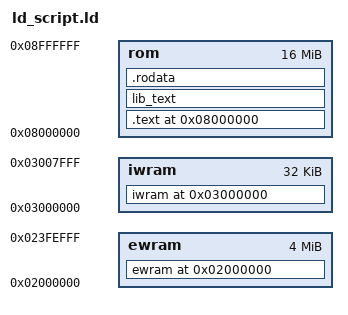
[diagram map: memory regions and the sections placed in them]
OUTPUT_FORMAT("elf32-littlearm", "elf32-bigarm", "elf32-littlearm")
OUTPUT_ARCH(arm)
MEMORY {
    ewram   : ORIGIN = 0x02000000, LENGTH = 4M - 4k
    iwram   : ORIGIN = 0x03000000, LENGTH = 32k
		rom     : ORIGIN = (0x08000000), LENGTH = 16M
}

SOUND_INFO_PTR = 0x03007FF0;

gMaxLines = 0;
gNumMusicPlayers = 32;

SECTIONS {
	. = 0x2000000;
	ewram (NOLOAD) :
	ALIGN(4)
    {
      gHeap = .;
      . = 0x20400;
      src/main.o(ewram_data);
      src/bg.o(ewram_data);
      src/camera.o(ewram_data);
      src/font.o(ewram_data);
      src/video.o(ewram_data);
      src/registry.o(ewram_data);
      src/utility_08237468.o(ewram_data);
      src/vm.o(ewram_data);
      src/code_08230e88.o(ewram_data);
      src/link.o(ewram_data);
      src/entity_0804e2c0.o(ewram_data);
    } >ewram = 0x00

	. = 0x3000000;
    iwram (NOLOAD) :
    ALIGN(4)
    {
      src/entity_08000a94.o(iwram_data);
      src/entity_08001610.o(iwram_data);
      src/main.o(iwram_data);
      src/entity_d9ae.o(iwram_data);
      src/entity_08004fac.o(iwram_data);
      src/message_choice.o(iwram_data);
      src/map_item.o(iwram_data);
      src/breakable.o(iwram_data);
      src/entity_2d2b.o(.bss);
      src/duneyrr_chandelier.o(.bss);
      src/entity_83b2.o(iwram_data);
      src/entity_0866.o(iwram_data);
      src/spirit_bugs.o(.bss);
      src/entity_329b.o(iwram_data);
      src/sun_countdown.o(iwram_data);
      src/shadow_normal.o(.bss);
      src/shadow_large.o(.bss);
      src/entity_080146e0.o(iwram_data);
      src/entity_08015220.o(iwram_data);
      src/entity_08015584.o(iwram_data);
      src/entity_08016ba4.o(iwram_data);
      src/mosaic_fader.o(.bss);
      src/item_icon_popup.o(.bss);
      src/entity_e435.o(iwram_data);
      src/weather.o(.bss);
      src/entity_517b.o(iwram_data);
      src/bgp_blend.o(iwram_data);
      src/entity_4b15.o(iwram_data);
      src/entity_12c4.o(iwram_data);
      src/entity_da0b.o(iwram_data);
      . = ALIGN(8);
      src/boss.o(iwram_data);
      src/entity_ab4e.o(iwram_data);
      src/message_window.o(iwram_data);
      src/text_marquee.o(iwram_data);
      src/text_panel.o(iwram_data);
      src/text_slideshow.o(iwram_data);
      src/joyspot.o(iwram_data);
      src/entity_0804e2c0.o(iwram_data);
      src/signal_strength_icon.o(iwram_data);
      src/entity_d53d.o(iwram_data);
      . = ALIGN(8);
      src/crossover_af33.o(iwram_data);
      src/entity_08051b70.o(iwram_data);
      src/entity_723e.o(iwram_data);
      src/entity_5645.o(.bss);
      src/entity_d438.o(.bss);
      src/dust.o(.bss);
      src/entity_08058ffc.o(iwram_data);
      src/damage_number.o(.bss);
      src/entity_08060470.o(iwram_data);
      src/explosion.o(iwram_data);
      src/menu.o(iwram_data);
      src/entity_5ccc.o(iwram_data);
      src/entity_1dbe.o(.bss);
      src/entity_ef66.o(iwram_data);
      src/entity_cf58.o(iwram_data);
      src/gameover.o(iwram_data);
      src/level_upper.o(iwram_data);
      src/entity_b3d1.o(iwram_data);
      src/emote.o(iwram_data);
      src/entity_080db520.o(iwram_data);
      src/entity_080dbe54.o(iwram_data);
      src/entity_080dc44c.o(iwram_data);
      src/entity_080dd1f8.o(iwram_data);
      src/attack_box.o(iwram_data);
      src/eff_smoke.o(.bss);
      src/entity_080df420.o(iwram_data);
      src/entity_080e01bc.o(iwram_data);
      src/entity_778b.o(iwram_data);
      src/enemy_target.o(.bss);
      src/entity_081d0e20.o(iwram_data);
      src/entity_081d16ec.o(iwram_data);
      src/entity_081d2180.o(iwram_data);
      src/elevator.o(iwram_data);
      src/bee_nest.o(iwram_data);
      src/entity_c60f.o(iwram_data);
      src/entity_7b9f.o(iwram_data);
      src/entity_8cc7.o(iwram_data);
      src/link_battle_lobby.o(.bss);
      src/entity_9a9f.o(iwram_data);
      src/link_battle_coin.o(iwram_data);
      src/entity_081e9cac.o(iwram_data);
      src/entity_081ea120.o(.bss);
      src/entity_081ea820.o(.bss);
      src/flamethrower.o(.bss);
      src/entity_081eb2f0.o(.bss);
      src/entity_081edcc4.o(.bss);
      src/entity_081ee2a0.o(.bss);
      src/entity_081ee7a8.o(.bss);
      src/entity_081eeb28.o(.bss);
      src/entity_081eee80.o(.bss);
      src/entity_081efa9c.o(.bss);
      src/entity_081f0298.o(.bss);
      src/entity_081f0b90.o(.bss);
      src/entity_081f1770.o(.bss);
      src/entity_081f26bc.o(.bss);
      src/entity_081f3324.o(.bss);
      src/entity_081f4554.o(.bss);
      src/entity_081f53a8.o(.bss);
      src/entity_081f73ec.o(.bss);
      src/entity_081f7974.o(.bss);
      src/entity_081f7de4.o(.bss);
      src/entity_081f8a28.o(.bss);
      src/entity_081f959c.o(.bss);
      src/entity_081f9cb8.o(.bss);
      src/entity_081fa164.o(.bss);
      src/entity_082034c0.o(.bss);
      src/entity_08203ad0.o(.bss);
      src/entity_08204cb8.o(.bss);
      src/actor/kuro.o(.bss);
      src/entity_8aab.o(iwram_data);
      . = ALIGN(8);
      src/interrupts.o(.bss);
      . = ALIGN(8);
      src/video.o(iwram_data);
      src/bg.o(iwram_data);
      src/video_reg.o(iwram_data);
      . = ALIGN(8);
      src/font.o(iwram_data);
      src/system_0823071c.o(iwram_data);
      src/code_08230e88.o(iwram_data);
      . = ALIGN(8);
      src/vm.o(iwram_data);
      src/vm_ctrl1.o(iwram_data);
      src/collision_map.o(iwram_data);
      src/hitbox.o(iwram_data);
      . = ALIGN(8);
      src/link.o(iwram_data);
      . = ALIGN(8);
      src/rfu.o(iwram_data);
      . = ALIGN(8);
      src/entity_0823acbc.o(iwram_data);
      src/vm_ctrl2.o(.bss);
      src/vm_subroutine.o(.bss);
      src/mover.o(.bss);
      src/entity_08240a54.o(.bss);
      src/entity_794c.o(.bss);
      src/zonelist.o(.bss);
      src/solar.o(.bss);
      src/eeprom.o(.bss);
      src/sound.o(.bss);
      src/eff_082473e0.o(.bss);
      src/solar_sensor.o(.bss);
      src/lib/libagbrtc.o(.bss);
      *libgcc.a:dp-bit.o(.bss);
      *libgcc.a:fp-bit.o(.bss);
      *libc.a:syscalls.o(.bss);
      src/lib/m4a.o(.bss.code);
      src/map_pltt_4ae5.o(COMMON);
      src/entity_6978.o(COMMON);
      src/cactus.o(COMMON);
      src/entity_c9bc.o(COMMON);
      src/entity_0800f110.o(COMMON);
      src/shadow_scripted.o(COMMON);
      src/entity_08016660.o(COMMON);
      src/weather.o(COMMON);
      src/msgbus.o(COMMON);
      src/actor.o(COMMON);
      src/joyspot.o(COMMON);
      src/entity_0804e2c0.o(COMMON);
      . = ALIGN(8);
      src/player.o(COMMON);
      src/enemy_entity_5941.o(COMMON);
      src/sabata_blackhole.o(COMMON);
      src/coffin.o(COMMON);
      src/menu.o(COMMON);
      src/entity_a628.o(COMMON);
      src/tasty_water.o(COMMON);
      src/solar_plant.o(COMMON);
      src/entity_3117.o(COMMON);
      src/entity_8af6.o(COMMON);
      src/entity_4063.o(COMMON);
      src/entity_080acd4c.o(COMMON);
      src/pile_driver.o(COMMON);
      src/enemy_manager.o(COMMON);
      src/link_connect.o(COMMON);
      src/entity_9a9f.o(COMMON);
      src/link_shop.o(COMMON);
      src/boss/dvalinn.o(COMMON);
      src/actor/otenko.o(COMMON);
      . = ALIGN(8);
      src/opening_runner.o(COMMON);
      src/video.o(COMMON);
      . = ALIGN(16);
      src/interrupts.o(COMMON);
      src/iwram2.o(COMMON);
      src/link.o(COMMON);
      src/lib/linkManager.o(COMMON);
      src/code_0823cd04.o(COMMON);
      src/camera.o(COMMON);
      src/time.o(COMMON);
      src/sound.o(COMMON);
      src/zonelist.o(COMMON);
      src/solar.o(COMMON);
      src/eeprom.o(COMMON);
      src/lib/m4a.o(COMMON);
      src/solar_sensor.o(COMMON);
      src/lib/librfu_stwi.o(iwram_data);
      . = ALIGN(16);
      src/lib/librfu_rfu.o(iwram_data);
      src/lib/librfu_sio32id.o(iwram_data);
      src/lib/agb_eeprom.o(iwram_data);
      end = .;
      *libc.a:sbrkr.o(COMMON);
    } >iwram = 0x00

    . = 0x8000000;
    .text :
    ALIGN(4)
    {
      src/rom_header.o (.text);
      src/crt0.o (.text);
			src/main.o (.text);
			src/entity_08000a94.o (.text);
			src/entity_08001610.o (.text);
			src/map_pltt_4ae5.o (.text);
			src/entity_6978.o (.text);
			src/entity_e28b.o (.text);
			src/entity_d9ae.o (.text);
			src/entity_08004fac.o (.text);
			src/message_choice.o (.text);
			src/map_item.o (.text);
			src/breakable.o (.text);
			src/entity_2d2b.o (.text);
			src/duneyrr_chandelier.o (.text);
			src/entity_83b2.o (.text);
			src/entity_0866.o (.text);
			src/spirit_bugs.o (.text);
			src/solar_bamboo.o (.text);
			src/cactus.o (.text);
			src/entity_c9bc.o (.text);
			src/entity_55c2.o (.text);
			src/entity_0800f110.o (.text);
			src/dungeon_title.o (.text);
			src/obp_blend.o (.text);
			src/entity_329b.o (.text);
			src/sun_countdown.o (.text);
			src/password_decoder.o (.text);
			src/save_sequence.o (.text);
			src/entity_e534.o (.text);
			src/password.o (.text);
			src/entity_ec96.o (.text);
			src/shadow_normal.o (.text);
			src/shadow_large.o (.text);
			src/shadow_scripted.o (.text);
			src/entity_080146e0.o (.text);
			src/entity_08015220.o (.text);
			src/entity_08015584.o (.text);
			src/entity_08016660.o (.text);
			src/entity_08016ba4.o (.text);
			src/mosaic_fader.o (.text);
			src/item_icon_popup.o (.text);
			src/entity_e435.o (.text);
			src/weather.o (.text);
			src/entity_517b.o (.text);
			src/entity_cf82.o (.text);
			src/entity_5e27.o (.text);
			src/bgp_blend.o (.text);
			src/entity_99ca.o (.text);
			src/entity_82b7.o (.text);
			src/entity_4b15.o (.text);
			src/entity_4f5c.o (.text);
			src/entity_fbe5.o (.text);
			src/entity_78c9.o (.text);
			src/entity_12c4.o (.text);
			src/entity_a687.o (.text);
			src/clock_alarm.o (.text);
			src/bgp_anim.o (.text);
			src/entity_da0b.o (.text);
			src/entity_ef6f.o (.text);
			src/door.o (.text);
			src/msgbus.o (.text);
			src/entity_730a.o (.text);
			src/boss.o (.text);
			src/boss/duneyrr.o (.text);
			src/boss/ringo.o (.text);
			src/boss/durathror.o (.text);
			src/boss/shademan_crossover.o (.text);
			src/actor.o (.text);
			src/entity_ab4e.o (.text);
			src/message_window.o (.text);
			src/text_renderer.o (.text);
			src/text_marquee.o (.text);
			src/text_panel.o (.text);
			src/text_slideshow.o (.text);
			src/entity_b88c.o (.text);
			src/joyspot.o (.text);
			src/entity_0804e2c0.o (.text);
			src/signal_strength_icon.o (.text);
			src/entity_d53d.o (.text);
			src/crossover_lobby.o (.text);
			src/crossover_af33.o (.text);
			src/entity_08051b70.o (.text);
			src/entity_08052250.o (.text);
			src/entity_723e.o (.text);
			src/entity_08052ffc.o (.text);
			src/entity_5645.o (.text);
			src/entity_56dc.o (.text);
			src/entity_8d5c.o (.text);
			src/entity_d438.o (.text);
			src/sprite_holder.o (.text);
			src/dust.o (.text);
			src/entity_08058ffc.o (.text);
			src/entity_08059a1c.o (.text);
			src/entity_0805a31c.o (.text);
			src/entity_0805b068.o (.text);
			src/entity_0805b790.o (.text);
			src/entity_0805d364.o (.text);
			src/entity_0805d79c.o (.text);
			src/entity_0805dcd4.o (.text);
			src/entity_0805e67c.o (.text);
			src/entity_0805ee80.o (.text);
			src/entity_0805f2dc.o (.text);
			src/entity_0805f68c.o (.text);
			src/damage_number.o (.text);
			src/entity_080601a8.o (.text);
			src/entity_08060470.o (.text);
			src/explosion.o (.text);
			src/player.o (.text);
			src/enemy_entity_5941.o (.text);
			src/django_berserk.o (.text);
			src/entity_08080be8.o (.text);
			src/sabata.o (.text);
			src/sabata_blackhole.o (.text);
			src/coffin.o (.text);
			src/entity_162e.o (.text);
			src/coffin_sealing.o (.text);
			src/menu.o (.text);
			src/entity_1b24.o (.text);
			src/entity_5ccc.o (.text);
			src/solar_station.o (.text);
			src/entity_1dbe.o (.text);
			src/entity_71ba.o (.text);
			src/entity_a628.o (.text);
			src/tasty_water.o (.text);
			src/entity_ef66.o (.text);
			src/alarm_panel.o (.text);
			src/entity_3db0.o (.text);
			src/solar_circle.o (.text);
			src/entity_a8f1.o (.text);
			src/entity_7c62.o (.text);
			src/time_magic_circle.o (.text);
			src/solar_plant.o (.text);
			src/entity_3117.o (.text);
			src/entity_8af6.o (.text);
			src/entity_cf58.o (.text);
			src/arrow_marker.o (.text);
			src/code_080a6c94.o (.text);
			src/mission_marker.o (.text);
			src/gameover.o (.text);
			src/freeze_effect.o (.text);
			src/level_upper.o (.text);
			src/entity_080a8ff8.o (.text);
			src/healing_effect.o (.text);
			src/entity_4063.o (.text);
			src/judgement.o (.text);
			src/morning_dew.o (.text);
			src/justice_tower.o (.text);
			src/dungeon_marker.o (.text);
			src/entity_080abd14.o (.text);
			src/eff_trans.o (.text);
			src/entity_080ac574.o (.text);
			src/entity_b6ff.o (.text);
			src/entity_080acd4c.o (.text);
			src/entity_5292.o (.text);
			src/pile_driver.o (.text);
			src/pile_driver_generator.o (.text);
			src/solar_bank.o (.text);
			src/dark_loans.o (.text);
			src/warehouse.o (.text);
			src/shop.o (.text);
			src/shop_item.o (.text);
			src/shop_weapon.o (.text);
			src/shop_coffin.o (.text);
			src/entity_b3d1.o (.text);
			src/soundbus.o (.text);
			src/entity_080c0fa0.o (.text);
			src/entity_3361.o (.text);
			src/entity_080c1abc.o (.text);
			src/entity_b87b.o (.text);
			src/boss/jormungandr.o (.text);
			src/entity_e06a.o (.text);
			src/entity_c814.o (.text);
			src/entity_080cbabc.o (.text);
			src/entity_f41a.o (.text);
			src/player_link.o (.text);
			src/entity_080d84f8.o (.text);
			src/emote.o (.text);
			src/entity_080db520.o (.text);
			src/entity_080dbe54.o (.text);
			src/entity_080dc44c.o (.text);
			src/entity_080dd1f8.o (.text);
			src/attack_box.o (.text);
			src/eff_smoke.o (.text);
			src/entity_080df420.o (.text);
			src/entity_080e01bc.o (.text);
			src/entity_778b.o (.text);
			src/entity_080e18e0.o (.text);
			src/enemy.o (.text);
			src/enemy_manager.o (.text);
			src/enemy_anim.o (.text);
			src/enedefault.o (.text);
			src/enemy_target.o (.text);
			src/enedefault2.o (.text);
			src/enemy/boku.o (.text);
			src/enemy/skeleton.o (.text);
			src/enemy/golem.o (.text);
			src/enemy/mummy.o (.text);
			src/enemy/spider.o (.text);
			src/enemy/centipede.o (.text);
			src/enemy/curoro.o (.text);
			src/enemy/bat.o (.text);
			src/enemy/crow.o (.text);
			src/enemy/mimic.o (.text);
			src/enemy/dog.o (.text);
			src/enemy/cockatrice.o (.text);
			src/enemy/slime.o (.text);
			src/enemy/bee.o (.text);
			src/enemy/ghost.o (.text);
			src/enemy/sandworm.o (.text);
			src/enemy/cheye.o (.text);
			src/enemy/octopus.o (.text);
			src/enemy/serpent.o (.text);
			src/enemy/ax.o (.text);
			src/enemy/root_of_darkness.o (.text);
			src/enemy/lich_flame_snake.o (.text);
			src/enemy/boku_link.o (.text);
			src/enemy/golem_link.o (.text);
			src/enemy/dog_link.o (.text);
			src/entity_081d0e20.o (.text);
			src/entity_081d16ec.o (.text);
			src/entity_081d2180.o (.text);
			src/elevator.o (.text);
			src/bee_nest.o (.text);
			src/entity_c60f.o (.text);
			src/entity_7b9f.o (.text);
			src/entity_8cc7.o (.text);
			src/link_connect.o (.text);
			src/entity_7999.o (.text);
			src/link_battle_rule.o (.text);
			src/link_battle_lobby.o (.text);
			src/link_battle_result.o (.text);
			src/entity_9a9f.o (.text);
			src/entity_501b.o (.text);
			src/link_battle_coin.o (.text);
			src/link_shop.o (.text);
			src/entity_8b8e.o (.text);
			src/entity_081e8d0c.o (.text);
			src/entity_081e9cac.o (.text);
			src/entity_081ea120.o (.text);
			src/entity_081ea820.o (.text);
			src/flamethrower.o (.text);
			src/entity_081eb2f0.o (.text);
			src/entity_081edcc4.o (.text);
			src/entity_081ee2a0.o (.text);
			src/entity_081ee7a8.o (.text);
			src/entity_081eeb28.o (.text);
			src/entity_081eee80.o (.text);
			src/entity_081efa9c.o (.text);
			src/entity_081f0298.o (.text);
			src/entity_081f0b90.o (.text);
			src/entity_081f1770.o (.text);
			src/entity_081f26bc.o (.text);
			src/entity_081f3324.o (.text);
			src/entity_081f4554.o (.text);
			src/entity_081f53a8.o (.text);
			src/entity_081f73ec.o (.text);
			src/entity_081f7974.o (.text);
			src/entity_081f7de4.o (.text);
			src/entity_081f8a28.o (.text);
			src/entity_081f959c.o (.text);
			src/entity_081f9cb8.o (.text);
			src/entity_081fa164.o (.text);
			src/entity_081fa1bc.o (.text);
			src/entity_3ffd.o (.text);
			src/nested_state.o (.text);
			src/boss/dvalinn.o (.text);
			src/entity_08202cd8.o (.text);
			src/entity_082034c0.o (.text);
			src/entity_08203ad0.o (.text);
			src/entity_082047f0.o (.text);
			src/entity_08204cb8.o (.text);
			src/actor/otenko.o (.text);
			src/actor/shaian.o (.text);
			src/actor/rita.o (.text);
			src/actor/zaji.o (.text);
			src/actor/sumire.o (.text);
			src/actor/kuro.o (.text);
			src/actor/kid.o (.text);
			src/actor/lady.o (.text);
			src/actor/coffin_seller.o (.text);
			src/actor/ennio.o (.text);
			src/actor/smith.o (.text);
			src/actor/dainn.o (.text);
			src/actor/rockman.o (.text);
			src/actor/misc.o (.text);
			src/enemy_dex.o (.text);
			src/preview_stage.o (.text);
			src/weapon_dex.o (.text);
			src/album_menu.o (.text);
			src/entity_4ddf.o (.text);
			src/title.o (.text);
			src/entity_a288.o (.text);
			src/entity_6367.o (.text);
			src/opening_runner.o (.text);
			src/code_0821b21c.o (.text);
			src/entity_0821b7fc.o (.text);
			src/entity_8ec8.o (.text);
			src/boss/shademan.o (.text);
			src/game_result.o (.text);
			src/entity_8aab.o (.text);
			src/interrupts.o (.text);
			src/video.o (.text);
			src/bg.o (.text);
			src/video_reg.o (.text);
			src/pltt.o (.text);
			src/particle.o (.text);
			src/font.o (.text);
			src/video_effect.o (.text);
			src/sprite_main.o (.text);
			src/sprite_main_arm.o (.text);
			src/system_0823071c.o (.text);
			src/malloc.o (.text);
			src/entity.o (.text);
			src/registry.o (.text);
			src/code_08230e88.o (.text);
			src/file.o (.text);
			src/vm.o (.text);
			src/vm_ctrl1.o (.text);
			src/vm_expr.o (.text);
			src/collision_map.o (.text);
			src/hitbox.o (.text);
			src/sprite_anim_aux.o (.text);
			src/sprite_anim_main.o (.text);
			src/utility_08237468.o (.text);
			src/math.o (.text);
			src/link.o (.text);
			src/lib/linkManager.o (.text);
			src/rfu.o (.text);
			src/demo.o (.text);
			src/entity_0823acbc.o (.text);
			src/vm_ctrl2.o (.text);
			src/vm_subroutine.o (.text);
			src/mover.o (.text);
			src/camera.o (.text);
			src/code_0823cd04.o (.text);
			src/delay.o (.text);
			src/time.o (.text);
			src/time_math.o (.text);
			src/sound.o (.text);
			src/entity_08240a54.o (.text);
			src/entity_794c.o (.text);
			src/savedata.o (.text);
			src/zonelist.o (.text);
			src/solar.o (.text);
			src/item/item.o (.text);
			src/item/weapon.o (.text);
			src/item/armor.o (.text);
			src/item/magic.o (.text);
			src/eeprom.o (.text);
    } >rom = 0x00

	lib_text :
	ALIGN(4)
	{
      src/lib/m4a_1.o (.text);
			src/lib/m4a.o (.text);
			src/homing_laser.o (.text);
			src/eff_082473e0.o (.text);
			src/solar_sensor.o (.text);
			src/lib/librfu_stwi.o (.text);
      src/lib/librfu_intr.o (.text);
      src/lib/librfu_rfu.o (.text);
      src/lib/librfu_sio32id.o (.text);
			src/rfu_0824beb8.o (.text);
			src/lib/libagbsyscall.o (.text);
			src/lib/agb_eeprom.o (.text);
			src/lib/libagbrtc.o (.text);
			*libgcc.a:*_call_via_rX*.o(.text);
			*libgcc.a:_divsi3.o(.text);
			*libgcc.a:_dvmd_tls.o(.text);
			*libgcc.a:_fixunsdfsi.o(.text);
			*libgcc.a:_udivsi3.o(.text);
			*libgcc.a:_umodsi3.o(.text);
			*libgcc.a:dp-bit.o(.text);
			*libgcc.a:fp-bit.o(.text);
			*libgcc.a:_lshrdi3.o(.text);
			*libgcc.a:_muldi3.o(.text);
			*libgcc.a:_negdi2.o(.text);
			src/lib/math/s_atan.o (.text);
			src/lib/math/s_cos.o (.text);
      src/lib/math/s_fabs.o (.text);
      src/lib/math/s_sin.o (.text);
      src/lib/math/s_tan.o (.text);
      src/lib/math/w_*.o (.text);
      src/lib/math/e_*.o (.text);
      src/lib/math/k_*.o (.text);
      src/lib/math/s_floor.o (.text);
			*libc.a:s_isnan.o(.text);
			src/lib/math/s_matherr.o (.text);
			*libc.a:s_scalbn.o(.text);
			*libc.a:s_copysign.o(.text);
			*libc.a:errno.o(.text);
			*libc.a:exit.o(.text);
			*libc.a:memcpy.o(.text);
			*libc.a:syscalls.o(.text);
			*libc.a:libcfunc.o(.text);
			*libc.a:strlen.o(.text);
			src/lib/ArmCpuFastSet.o (.text);
	} >rom = 0x00

	.rodata :
	ALIGN(4)
	{
    src/entity_e28b.o (.rodata);
    src/message_choice.o (.rodata);
    src/entity_4b15.o (.rodata);
    src/text_renderer.o (.rodata.string);
    src/joyspot.o (.rodata.string);
    src/entity_0804e2c0.o (.rodata.faraddr);
    src/data.o (.rodata);
    src/entity_1b24.o (.rodata);
    src/pile_driver.o (.rodata.string);
    src/boss/jormungandr.o (.rodata.string);
    src/entity_f41a.o (.rodata);
    src/enemy.o (.rodata.string);
    src/data2.o (.rodata);
    src/entity_4ddf.o (.rodata.faraddr);
    src/title.o (.rodata.faraddr);
    src/entity_a288.o (.rodata.faraddr);
    src/boss/shademan.o (.rodata.faraddr);
    src/game_result.o (.rodata.faraddr);
    src/interrupts.o (.rodata);
    src/lib/m4a_tables.o (.rodata);
    src/sound.o (.rodata);
    src/data/songs.o (.rodata);
    src/lib/librfu_rfu.o (.rodata);
    src/lib/librfu_sio32id.o (.rodata);
    src/lib/agb_eeprom_data.o (.rodata);
    src/lib/libagbrtc.o (.rodata);
    src/lib/math/s_atan.o (.rodata);
    src/lib/math/s_cos.o (.rodata);
    src/lib/math/s_fabs.o (.rodata);
    src/lib/math/s_sin.o (.rodata);
    src/lib/math/s_tan.o (.rodata);
    src/lib/math/w_acos.o (.rodata);
    src/lib/math/w_asin.o (.rodata);
    src/lib/math/w_fmod.o (.rodata);
    src/lib/math/e_acos.o (.rodata);
    src/lib/math/e_asin.o (.rodata);
    src/lib/math/e_fmod.o (.rodata);
    src/lib/math/e_rem_pio2.o (.rodata);
    src/lib/math/e_sqrt.o (.rodata);
    src/lib/math/k_cos.o (.rodata);
    src/lib/math/k_rem_pio2.o (.rodata);
    src/lib/math/k_sin.o (.rodata);
    src/lib/math/k_tan.o (.rodata);
    src/lib/math/s_floor.o (.rodata);
    *libc.a:s_scalbn.o(.rodata);
    *libc.a:impure.o(.rodata);
    *libc.a:syscalls.o(.rodata);
    src/vm_commands.o (.rodata);
    src/map_pltt_4ae5.o (.rodata);
    src/entity_d9ae.o (.rodata);
    src/entity_2d2b.o (.rodata);
    src/duneyrr_chandelier.o (.rodata);
    src/entity_83b2.o (.rodata);
    src/entity_0866.o (.rodata);
    src/spirit_bugs.o (.rodata);
    src/solar_bamboo.o (.rodata);
    src/entity_c9bc.o (.rodata);
    src/entity_0800f110.o (.rodata);
    src/entity_329b.o (.rodata);
    src/entity_e534.o (.rodata);
    src/password.o (.rodata);
    src/entity_080146e0.o (.rodata);
    src/entity_08015220.o (.rodata);
    src/entity_08015584.o (.rodata);
    src/entity_08016660.o (.rodata);
    src/mosaic_fader.o (.rodata);
    src/item_icon_popup.o (.rodata);
    src/weather.o (.rodata);
    src/entity_cf82.o (.rodata);
    src/entity_5e27.o (.rodata);
    src/entity_4f5c.o (.rodata);
    src/entity_78c9.o (.rodata);
    src/entity_ef6f.o (.rodata);
    src/door.o (.rodata);
    src/boss/duneyrr.o (.rodata);
    src/boss/ringo.o (.rodata);
    src/boss/durathror.o (.rodata);
    src/boss/shademan_crossover.o (.rodata);
    src/actor.o (.rodata);
    src/entity_ab4e.o (.rodata);
    src/text_renderer.o (.rodata);
    src/text_marquee.o (.rodata);
    src/text_slideshow.o (.rodata);
    src/entity_b88c.o (.rodata);
    src/joyspot.o (.rodata);
    src/entity_0804e2c0.o (.rodata);
    src/entity_d53d.o (.rodata);
    src/crossover_lobby.o (.rodata);
    src/crossover_af33.o (.rodata);
    src/entity_08051b70.o (.rodata);
    src/entity_08052250.o (.rodata);
    src/entity_723e.o (.rodata);
    src/entity_08052ffc.o (.rodata);
    src/entity_5645.o (.rodata);
    src/dust.o (.rodata);
    src/entity_08058ffc.o (.rodata);
    src/entity_08059a1c.o (.rodata);
    src/entity_0805a31c.o (.rodata);
    src/entity_0805b068.o (.rodata);
    src/entity_0805b790.o (.rodata);
    src/entity_0805d364.o (.rodata);
    src/entity_0805e67c.o (.rodata);
    src/entity_0805ee80.o (.rodata);
    src/damage_number.o (.rodata);
    src/entity_080601a8.o (.rodata);
    src/entity_08060470.o (.rodata);
    src/player.o (.rodata);
    src/sabata.o (.rodata);
    src/sabata_blackhole.o (.rodata);
    src/coffin.o (.rodata);
    src/coffin_sealing.o (.rodata);
    src/menu.o (.rodata);
    src/entity_5ccc.o (.rodata);
    src/gameover.o (.rodata);
    src/pile_driver.o (.rodata);
    src/pile_driver_generator.o (.rodata);
    src/boss/jormungandr.o (.rodata);
    src/player_link.o (.rodata);
    src/emote.o (.rodata);
    src/entity_080db520.o (.rodata);
    src/entity_080dbe54.o (.rodata);
    src/entity_080dc44c.o (.rodata);
    src/entity_080dd1f8.o (.rodata);
    src/attack_box.o (.rodata);
    src/entity_080df420.o (.rodata);
    src/entity_080e01bc.o (.rodata);
    src/entity_778b.o (.rodata);
    src/enemy.o (.rodata);
    src/enedefault.o (.rodata);
    src/enemy/boku.o (.rodata);
    src/enemy/skeleton.o (.rodata);
    src/enemy/golem.o (.rodata);
    src/enemy/mummy.o (.rodata);
    src/enemy/spider.o (.rodata);
    src/enemy/centipede.o (.rodata);
    src/enemy/curoro.o (.rodata);
    src/enemy/bat.o (.rodata);
    src/enemy/crow.o (.rodata);
    src/enemy/mimic.o (.rodata);
    src/enemy/dog.o (.rodata);
    src/enemy/cockatrice.o (.rodata);
    src/enemy/slime.o (.rodata);
    src/enemy/bee.o (.rodata);
    src/enemy/ghost.o (.rodata);
    src/enemy/sandworm.o (.rodata);
    src/enemy/cheye.o (.rodata);
    src/enemy/octopus.o (.rodata);
    src/enemy/serpent.o (.rodata);
    src/enemy/ax.o (.rodata);
    src/enemy/root_of_darkness.o (.rodata);
    src/enemy/lich_flame_snake.o (.rodata);
    src/enemy/boku_link.o (.rodata);
    src/enemy/golem_link.o (.rodata);
    src/enemy/dog_link.o (.rodata);
    src/entity_081d0e20.o (.rodata);
    src/entity_081d16ec.o (.rodata);
    src/entity_081d2180.o (.rodata);
    src/elevator.o (.rodata);
    src/bee_nest.o (.rodata);
    src/entity_c60f.o (.rodata);
    src/entity_8cc7.o (.rodata);
    src/entity_7999.o (.rodata);
    src/link_battle_rule.o (.rodata);
    src/link_battle_lobby.o (.rodata);
    src/link_battle_result.o (.rodata);
    src/entity_9a9f.o (.rodata);
    src/entity_8b8e.o (.rodata);
    src/entity_081e8d0c.o (.rodata);
    src/entity_081ea120.o (.rodata);
    src/entity_081ea820.o (.rodata);
    src/flamethrower.o (.rodata);
    src/entity_081eb2f0.o (.rodata);
    src/entity_081edcc4.o (.rodata);
    src/entity_081ee2a0.o (.rodata);
    src/entity_081ee7a8.o (.rodata);
    src/entity_081eeb28.o (.rodata);
    src/entity_081eee80.o (.rodata);
    src/entity_081efa9c.o (.rodata);
    src/entity_081f0298.o (.rodata);
    src/entity_081f0b90.o (.rodata);
    src/entity_081f1770.o (.rodata);
    src/entity_081f26bc.o (.rodata);
    src/entity_081f3324.o (.rodata);
    src/entity_081f4554.o (.rodata);
    src/entity_081f53a8.o (.rodata);
    src/entity_081f73ec.o (.rodata);
    src/entity_081f7974.o (.rodata);
    src/entity_081f7de4.o (.rodata);
    src/entity_081f8a28.o (.rodata);
    src/entity_081f959c.o (.rodata);
    src/entity_081f9cb8.o (.rodata);
    src/entity_081fa164.o (.rodata);
    src/boss/dvalinn.o (.rodata);
    src/entity_08202cd8.o (.rodata);
    src/entity_082034c0.o (.rodata);
    src/entity_082047f0.o (.rodata);
    src/entity_08204cb8.o (.rodata);
    src/actor/otenko.o (.rodata);
    src/actor/shaian.o (.rodata);
    src/actor/rita.o (.rodata);
    src/actor/zaji.o (.rodata);
    src/actor/sumire.o (.rodata);
    src/actor/kuro.o (.rodata);
    src/actor/kid.o (.rodata);
    src/actor/lady.o (.rodata);
    src/actor/coffin_seller.o (.rodata);
    src/actor/ennio.o (.rodata);
    src/actor/smith.o (.rodata);
    src/actor/dainn.o (.rodata);
    src/actor/rockman.o (.rodata);
    src/actor/misc.o (.rodata);
    src/enemy_dex.o (.rodata);
    src/preview_stage.o (.rodata);
    src/weapon_dex.o (.rodata);
    src/album_menu.o (.rodata);
    src/title.o (.rodata);
    src/entity_a288.o (.rodata);
    src/entity_6367.o (.rodata);
    src/opening_runner.o (.rodata);
    src/boss/shademan.o (.rodata);
    src/game_result.o (.rodata);
    src/entity_8aab.o (.rodata);
    src/video.o (.rodata);
    src/bg.o (.rodata);
    src/video_reg.o (.rodata);
    src/video_effect.o (.rodata);
    src/entity.o (.rodata);
    src/vm.o (.rodata);
    src/vm_ctrl1.o (.rodata);
    src/utility_08237468.o (.rodata);
    src/math.o (.rodata);
    src/file.o (.rodata);
    src/data/sprite_animation.o (.rodata);
    src/data/tilemap.o (.rodata);
    src/data/collision_map.o (.rodata);
    src/data/bgp.o (.rodata);
    src/data/tilesets.o (.rodata);
    src/data/fonts.o (.rodata);
    src/data/particle.o (.rodata);
    src/data/sprite_aux.o (.rodata);
    src/data/sprite_main.o (.rodata);
    src/data/obp.o (.rodata);
    src/data/scripts.o (.rodata);
    src/item/data.o (.rodata);
    src/demo.o (.rodata);
    src/vm_ctrl2.o (.rodata);
    src/solar.o (.rodata);
    src/homing_laser.o (.rodata);
    src/eff_082473e0.o (.rodata);
    src/solar_sensor.o (.rodata);
    src/code_0823cd04.o (.rodata);

    /* ????????????? */
    *libc.a:impure.o(.data);
	} >rom = 0x00

    /* Discard everything not specifically mentioned above. */
	/DISCARD/ :
    {
        *(*);
    }
}
